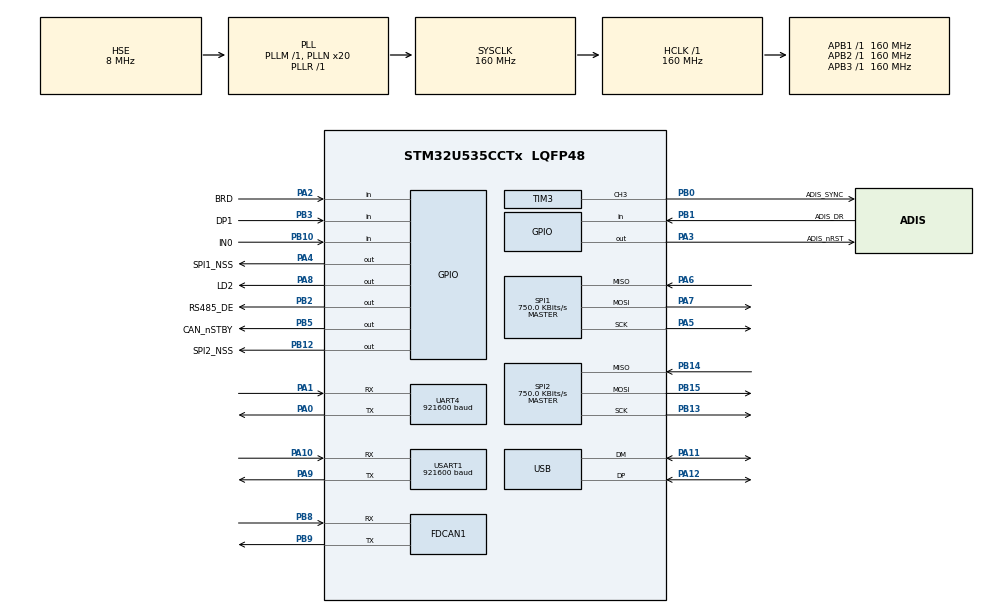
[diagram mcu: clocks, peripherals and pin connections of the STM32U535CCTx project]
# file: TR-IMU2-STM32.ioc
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CORTEX_M33_NS.userName=CORTEX_M33
FDCAN1.CalculateBaudRateNominal=500000
FDCAN1.CalculateTimeBitNominal=2000
FDCAN1.CalculateTimeQuantumNominal=125.0
FDCAN1.ClockDivider=FDCAN_CLOCK_DIV1
FDCAN1.DataPrescaler=2
FDCAN1.DataSyncJumpWidth=4
FDCAN1.DataTimeSeg1=15
FDCAN1.DataTimeSeg2=4
FDCAN1.FrameFormat=FDCAN_FRAME_FD_BRS
FDCAN1.NominalPrescaler=10
FDCAN1.NominalSyncJumpWidth=2
FDCAN1.NominalTimeSeg1=13
FDCAN1.NominalTimeSeg2=2
FDCAN1.ProtocolException=DISABLE
FDCAN1.StdFiltersNbr=1
GPDMA1.IPHANDLE_GPDMACH1-SIMPLEREQUEST_GPDMACH1=__NULL
GPDMA1.IPHANDLE_GPDMACH3-SIMPLEREQUEST_GPDMACH3=__NULL
GPDMA1.LINKEDLISTMODE_GPDMACH0=DMA_LINKEDLIST_CIRCULAR
GPDMA1.LINKEDLISTMODE_GPDMACH2=DMA_LINKEDLIST_CIRCULAR
GPDMA1.PRIORITY_LL_GPDMACH0=DMA_LOW_PRIORITY_HIGH_WEIGHT
GPDMA1.PRIORITY_LL_GPDMACH2=DMA_LOW_PRIORITY_HIGH_WEIGHT
GPDMA1.REQUEST_GPDMACH1=GPDMA1_REQUEST_USART1_TX
GPDMA1.REQUEST_GPDMACH3=GPDMA1_REQUEST_UART4_TX
GPDMA1.SRCINC_GPDMACH1=DMA_SINC_INCREMENTED
GPDMA1.SRCINC_GPDMACH3=DMA_SINC_INCREMENTED
GPDMA1.TRANSFERALLOCATEDPORTDEST_GPDMACH1=DMA_DEST_ALLOCATED_PORT1
GPDMA1.TRANSFERALLOCATEDPORTDEST_GPDMACH3=DMA_DEST_ALLOCATED_PORT1
GPDMA1.TRANSFERALLOCATEDPORTSRC_GPDMACH1=DMA_SRC_ALLOCATED_PORT1
GPDMA1.TRANSFERALLOCATEDPORTSRC_GPDMACH3=DMA_SRC_ALLOCATED_PORT1
IWDG.Prescaler=IWDG_PRESCALER_16
Linkedlist.MDMA_Channel0.GP_SW.0.BlkHWRequest=DMA_BREQ_SINGLE_BURST
Linkedlist.MDMA_Channel0.GP_SW.0.DataHandling=NONE
Linkedlist.MDMA_Channel0.GP_SW.0.DataSize=0
Linkedlist.MDMA_Channel0.GP_SW.0.DestBurstLength=1
Linkedlist.MDMA_Channel0.GP_SW.0.DestDataWidth=DMA_DEST_DATAWIDTH_BYTE
Linkedlist.MDMA_Channel0.GP_SW.0.DestInc=DMA_DINC_INCREMENTED
Linkedlist.MDMA_Channel0.GP_SW.0.Direction=DMA_PERIPH_TO_MEMORY
Linkedlist.MDMA_Channel0.GP_SW.0.DstAddress=0
Linkedlist.MDMA_Channel0.GP_SW.0.Instance=MDMA_Channel0
Linkedlist.MDMA_Channel0.GP_SW.0.LL_CIRCULARNODE=Node_GPDMA1_Channel0
Linkedlist.MDMA_Channel0.GP_SW.0.LL_MASTERDMA=GPDMA
Linkedlist.MDMA_Channel0.GP_SW.0.LL_NAME=UART1Node
Linkedlist.MDMA_Channel0.GP_SW.0.LL_TYPE=CIRCULAR
Linkedlist.MDMA_Channel0.GP_SW.0.NODE_NAME=UART1_RX_node
Linkedlist.MDMA_Channel0.GP_SW.0.Requestforcodegen=GPDMA1_REQUEST_USART1_RX
Linkedlist.MDMA_Channel0.GP_SW.0.SrcAddress=0
Linkedlist.MDMA_Channel0.GP_SW.0.SrcBurstLength=1
Linkedlist.MDMA_Channel0.GP_SW.0.SrcDataWidth=DMA_SRC_DATAWIDTH_BYTE
Linkedlist.MDMA_Channel0.GP_SW.0.SrcInc=DMA_SINC_FIXED
Linkedlist.MDMA_Channel0.GP_SW.0.TransferAllocatedPortDest=DMA_DEST_ALLOCATED_PORT0
Linkedlist.MDMA_Channel0.GP_SW.0.TransferAllocatedPortSrc=DMA_SRC_ALLOCATED_PORT0
Linkedlist.MDMA_Channel0.GP_SW.0.TransferEventMode=DMA_TCEM_BLOCK_TRANSFER
Linkedlist.MDMA_Channel0.GP_SW.0.TriggerPolarity=DMA_TRIG_POLARITY_MASKED
Linkedlist.MDMA_Channel0.Request0=GP_SW
Linkedlist.MDMA_Channel0.RequestsNb=1
Linkedlist.MDMA_Channel1.GP_SW.0.BlkHWRequest=DMA_BREQ_SINGLE_BURST
Linkedlist.MDMA_Channel1.GP_SW.0.DataHandling=NONE
Linkedlist.MDMA_Channel1.GP_SW.0.DataSize=0
Linkedlist.MDMA_Channel1.GP_SW.0.DestBurstLength=1
Linkedlist.MDMA_Channel1.GP_SW.0.DestDataWidth=DMA_DEST_DATAWIDTH_BYTE
Linkedlist.MDMA_Channel1.GP_SW.0.DestInc=DMA_DINC_INCREMENTED
Linkedlist.MDMA_Channel1.GP_SW.0.Direction=DMA_PERIPH_TO_MEMORY
Linkedlist.MDMA_Channel1.GP_SW.0.DstAddress=0
Linkedlist.MDMA_Channel1.GP_SW.0.Instance=MDMA_Channel1
Linkedlist.MDMA_Channel1.GP_SW.0.LL_CIRCULARNODE=Node_GPDMA1_Channel2
Linkedlist.MDMA_Channel1.GP_SW.0.LL_MASTERDMA=GPDMA
Linkedlist.MDMA_Channel1.GP_SW.0.LL_NAME=UART4Node
Linkedlist.MDMA_Channel1.GP_SW.0.LL_TYPE=CIRCULAR
Linkedlist.MDMA_Channel1.GP_SW.0.NODE_NAME=UART4_RX_node
Linkedlist.MDMA_Channel1.GP_SW.0.Requestforcodegen=GPDMA1_REQUEST_UART4_RX
Linkedlist.MDMA_Channel1.GP_SW.0.SrcAddress=0
Linkedlist.MDMA_Channel1.GP_SW.0.SrcBurstLength=1
Linkedlist.MDMA_Channel1.GP_SW.0.SrcDataWidth=DMA_SRC_DATAWIDTH_BYTE
Linkedlist.MDMA_Channel1.GP_SW.0.SrcInc=DMA_SINC_FIXED
Linkedlist.MDMA_Channel1.GP_SW.0.TransferAllocatedPortDest=DMA_DEST_ALLOCATED_PORT0
Linkedlist.MDMA_Channel1.GP_SW.0.TransferAllocatedPortSrc=DMA_SRC_ALLOCATED_PORT0
Linkedlist.MDMA_Channel1.GP_SW.0.TransferEventMode=DMA_TCEM_BLOCK_TRANSFER
Linkedlist.MDMA_Channel1.GP_SW.0.TriggerPolarity=DMA_TRIG_POLARITY_MASKED
Linkedlist.MDMA_Channel1.Request0=GP_SW
Linkedlist.MDMA_Channel1.RequestsNb=1
Linkedlist.RequestSet0=MDMA_Channel0
Linkedlist.RequestSet1=MDMA_Channel1
Linkedlist.RequestSetsNb=2
Mcu.Family=STM32U5
Mcu.Name=STM32U535CCTx
Mcu.Package=LQFP48
NVIC.FDCAN1_IT0_IRQn=true\:2\:0\:true\:false\:true\:true\:true\:true
NVIC.GPDMA1_Channel0_IRQn=true\:2\:0\:true\:false\:true\:true\:true\:true
NVIC.GPDMA1_Channel1_IRQn=true\:2\:0\:true\:false\:true\:false\:true\:true
NVIC.GPDMA1_Channel2_IRQn=true\:2\:0\:true\:false\:true\:true\:true\:true
NVIC.GPDMA1_Channel3_IRQn=true\:2\:0\:true\:false\:true\:false\:true\:true
NVIC.PriorityGroup=NVIC_PRIORITYGROUP_4
NVIC.SPI1_IRQn=true\:1\:0\:true\:false\:true\:true\:true\:true
NVIC.SPI2_IRQn=true\:1\:0\:true\:false\:true\:true\:true\:true
NVIC.TIM6_IRQn=true\:1\:0\:true\:false\:true\:true\:true\:true
NVIC.UART4_IRQn=true\:2\:0\:true\:false\:true\:true\:true\:true
NVIC.USART1_IRQn=true\:2\:0\:true\:false\:true\:true\:true\:true
NVIC.USB_IRQn=true\:0\:0\:true\:false\:true\:true\:true\:true
PA0.GPIO_PuPd=GPIO_PULLUP
PA0.GPIO_Speed=GPIO_SPEED_FREQ_HIGH
PA0.Mode=Asynchronous
PA0.Signal=UART4_TX
PA1.GPIO_PuPd=GPIO_PULLUP
PA1.GPIO_Speed=GPIO_SPEED_FREQ_HIGH
PA1.Mode=Asynchronous
PA1.Signal=UART4_RX
PA10.Mode=Asynchronous
PA10.Signal=USART1_RX
PA11.Mode=Device
PA11.Signal=USB_DM
PA12.Mode=Device
PA12.Signal=USB_DP
PA13\ (JTMS/SWDIO).Mode=Serial_Wire
PA13\ (JTMS/SWDIO).Signal=DEBUG_JTMS-SWDIO
PA14\ (JTCK/SWCLK).Mode=Serial_Wire
PA14\ (JTCK/SWCLK).Signal=DEBUG_JTCK-SWCLK
PA2.GPIO_Label=BRD
PA2.Signal=GPIO_Input
PA3.GPIO_Label=ADIS_nRST
PA3.GPIO_ModeDefaultOutputPP=GPIO_MODE_OUTPUT_OD
PA3.GPIO_PuPd=GPIO_NOPULL
PA3.PinState=GPIO_PIN_SET
PA3.Signal=GPIO_Output
PA4.GPIO_Label=SPI1_NSS
PA4.GPIO_Speed=GPIO_SPEED_FREQ_VERY_HIGH
PA4.PinState=GPIO_PIN_SET
PA4.Signal=GPIO_Output
PA5.GPIO_Speed=GPIO_SPEED_FREQ_VERY_HIGH
PA5.Mode=Full_Duplex_Master
PA5.Signal=SPI1_SCK
PA6.GPIO_Speed=GPIO_SPEED_FREQ_VERY_HIGH
PA6.Mode=Full_Duplex_Master
PA6.Signal=SPI1_MISO
PA7.GPIO_Speed=GPIO_SPEED_FREQ_VERY_HIGH
PA7.Mode=Full_Duplex_Master
PA7.Signal=SPI1_MOSI
PA8.GPIO_Label=LD2
PA8.GPIO_ModeDefaultOutputPP=GPIO_MODE_OUTPUT_OD
PA8.GPIO_PuPd=GPIO_NOPULL
PA8.PinState=GPIO_PIN_SET
PA8.Signal=GPIO_Output
PA9.Mode=Asynchronous
PA9.Signal=USART1_TX
PB0.GPIO_Label=ADIS_SYNC
PB0.GPIO_Speed=GPIO_SPEED_FREQ_HIGH
PB0.Signal=S_TIM3_CH3
PB1.GPIO_Label=ADIS_DR
PB1.Signal=GPIO_Input
PB10.GPIO_Label=IN0
PB10.Signal=GPIO_Input
PB12.GPIO_Label=SPI2_NSS
PB12.GPIO_Speed=GPIO_SPEED_FREQ_VERY_HIGH
PB12.PinState=GPIO_PIN_SET
PB12.Signal=GPIO_Output
PB13.GPIO_Speed=GPIO_SPEED_FREQ_VERY_HIGH
PB13.Mode=Full_Duplex_Master
PB13.Signal=SPI2_SCK
PB14.GPIO_Speed=GPIO_SPEED_FREQ_VERY_HIGH
PB14.Mode=Full_Duplex_Master
PB14.Signal=SPI2_MISO
PB15.GPIO_Speed=GPIO_SPEED_FREQ_VERY_HIGH
PB15.Mode=Full_Duplex_Master
PB15.Signal=SPI2_MOSI
PB2.GPIO_Label=RS485_DE
PB2.GPIO_ModeDefaultOutputPP=GPIO_MODE_OUTPUT_PP
PB2.GPIO_PuPd=GPIO_NOPULL
PB2.GPIO_Speed=GPIO_SPEED_FREQ_HIGH
PB2.PinState=GPIO_PIN_RESET
PB2.Signal=GPIO_Output
PB3\ (JTDO/TRACESWO).GPIO_Label=DP1
PB3\ (JTDO/TRACESWO).GPIO_PuPd=GPIO_PULLUP
PB3\ (JTDO/TRACESWO).Signal=GPIO_Input
PB5.GPIO_Label=CAN_nSTBY
PB5.GPIO_ModeDefaultOutputPP=GPIO_MODE_OUTPUT_OD
PB5.GPIO_PuPd=GPIO_NOPULL
PB5.PinState=GPIO_PIN_SET
PB5.Signal=GPIO_Output
PB8.Mode=FDCAN_Activate
PB8.Signal=FDCAN1_RX
PB9.Mode=FDCAN_Activate
PB9.Signal=FDCAN1_TX
PH0-OSC_IN\ (PH0).Mode=HSE-External-Oscillator
PH0-OSC_IN\ (PH0).Signal=RCC_OSC_IN
PH1-OSC_OUT\ (PH1).Mode=HSE-External-Oscillator
PH1-OSC_OUT\ (PH1).Signal=RCC_OSC_OUT
ProjectManager.HeapSize=0x800
ProjectManager.StackSize=0x800
ProjectManager.TargetToolchain=STM32CubeIDE
RCC.ADCFreq_Value=16000000
RCC.AHBFreq_Value=160000000
RCC.APB1Freq_Value=160000000
RCC.APB1TimFreq_Value=160000000
RCC.APB2Freq_Value=160000000
RCC.APB2TimFreq_Value=160000000
RCC.APB3Freq_Value=160000000
RCC.CortexFreq_Value=160000000
RCC.DACCLockSelectionVirtual=RCC_DAC1CLKSOURCE_LSI
RCC.DACCLockSelectionVirtualString=RCC_DAC1CLKSOURCE_LSI
RCC.EPOD_VALUE=8000000
RCC.HCLKFreq_Value=160000000
RCC.HSE_VALUE=8000000
RCC.HSI48_VALUE=48000000
RCC.HSI_VALUE=16000000
RCC.LSE_VALUE=32768
RCC.LSIDIV_VALUE=32000
RCC.MSIClockRange=RCC_MSIRANGE_0
RCC.MSIKClockRange=RCC_MSIKRANGE_1
RCC.MSI_VALUE=48000000
RCC.PLL1R=1
RCC.PLL2FRACN=0
RCC.PLL3FRACN=0
RCC.PLLFRACN=0
RCC.PLLN=20
RCC.PLLSourceVirtual=RCC_PLLSOURCE_HSE
RCC.SPI1CLockSelection=RCC_SPI1CLKSOURCE_MSIK
RCC.SPI2CLockSelection=RCC_SPI2CLKSOURCE_MSIK
RCC.SYSCLKFreq_VALUE=160000000
RCC.SYSCLKSource=RCC_SYSCLKSOURCE_PLLCLK
RCC.USBFreq_Value=48000000
RCC.VCOOutputFreq_Value=160000000
SH.S_TIM3_CH3.0=TIM3_CH3,PWM Generation3 CH3
SPI1.BaudRatePrescaler=SPI_BAUDRATEPRESCALER_32
SPI1.CLKPhase=SPI_PHASE_2EDGE
SPI1.CLKPolarity=SPI_POLARITY_HIGH
SPI1.CalculateBaudRate=750.0 KBits/s
SPI1.DataSize=SPI_DATASIZE_16BIT
SPI1.Direction=SPI_DIRECTION_2LINES
SPI1.Mode=SPI_MODE_MASTER
SPI1.VirtualType=VM_MASTER
SPI2.BaudRatePrescaler=SPI_BAUDRATEPRESCALER_32
SPI2.CLKPhase=SPI_PHASE_2EDGE
SPI2.CLKPolarity=SPI_POLARITY_HIGH
SPI2.CalculateBaudRate=750.0 KBits/s
SPI2.DataSize=SPI_DATASIZE_16BIT
SPI2.Direction=SPI_DIRECTION_2LINES
SPI2.Mode=SPI_MODE_MASTER
SPI2.VirtualType=VM_MASTER
TIM3.AutoReloadPreload=TIM_AUTORELOAD_PRELOAD_ENABLE
TIM3.Channel-PWM\ Generation3\ CH3=TIM_CHANNEL_3
TIM3.PeriodNoDither=5786
TIM3.Prescaler=2
TIM3.PulseNoDither_3=2500
TIM6.PeriodNoDither=159
TIM6.Prescaler=15
TIM6.TIM_MasterOutputTrigger=TIM_TRGO_UPDATE
UART4.BaudRate=921600
USART1.BaudRate=921600
USART1.VirtualMode-Asynchronous=VM_ASYNC
VP_DCACHE1_VS_DCACHE.Mode=DCACHE_Activate
VP_GPDMA1_VS_GPDMACH0.Mode=LINKEDLIST_GPDMACH0
VP_GPDMA1_VS_GPDMACH1.Mode=SIMPLEREQUEST_GPDMACH1
VP_GPDMA1_VS_GPDMACH2.Mode=LINKEDLIST_GPDMACH2
VP_GPDMA1_VS_GPDMACH3.Mode=SIMPLEREQUEST_GPDMACH3
VP_ICACHE_VS_ICACHE.Mode=DefaultMode
VP_IWDG_VS_IWDG.Mode=IWDG_Activate
VP_LPBAMQUEUE_VS_QUEUE.Mode=QUEUEMODE
VP_LPBAM_VS_SIG1.Mode=SmartRun
VP_LPBAM_VS_SIG4.Mode=LPDMA1
VP_MEMORYMAP_VS_MEMORYMAP.Mode=CurAppReg
VP_PWR_VS_SECSignals.Mode=Security/Privilege
VP_TIM3_VS_ClockSourceINT.Mode=Internal
VP_TIM6_VS_ClockSourceINT.Mode=Enable_Timer
VP_TIM6_VS_OPM.Mode=OPM_bit
board=custom

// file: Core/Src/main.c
/* USER CODE BEGIN Header */
/**
  ******************************************************************************
  * @file           : main.c
  * @brief          : Main program body
  ******************************************************************************
  * @attention
  *
  * Copyright (c) 2025 STMicroelectronics.
  * All rights reserved.
  *
  * This software is licensed under terms that can be found in the LICENSE file
  * in the root directory of this software component.
  * If no LICENSE file comes with this software, it is provided AS-IS.
  *
  ******************************************************************************
  */
/* USER CODE END Header */
#include "main.h"

/* USER CODE BEGIN Includes */
#include "libraries.h"
/* USER CODE END Includes */

DCACHE_HandleTypeDef hdcache1;

FDCAN_HandleTypeDef hfdcan1;

DMA_HandleTypeDef handle_GPDMA1_Channel2;
DMA_HandleTypeDef handle_GPDMA1_Channel0;

UART_HandleTypeDef huart4;
UART_HandleTypeDef huart1;
DMA_HandleTypeDef handle_GPDMA1_Channel3;
DMA_HandleTypeDef handle_GPDMA1_Channel1;

PCD_HandleTypeDef hpcd_USB_DRD_FS;

void SystemClock_Config(void);
static void MX_GPIO_Init(void);
static void MX_GPDMA1_Init(void);
static void MX_ICACHE_Init(void);
static void MX_DCACHE1_Init(void);
static void MX_SPI1_Init(void);
static void MX_SPI2_Init(void);
static void MX_TIM3_Init(void);
static void MX_TIM6_Init(void);
static void MX_FDCAN1_Init(void);
static void MX_USART1_UART_Init(void);
static void MX_UART4_Init(void);
static void MX_USB_DRD_FS_PCD_Init(void);

int main(void)
{

  /* MCU Configuration--------------------------------------------------------*/

  /* Reset of all peripherals, Initializes the Flash interface and the Systick. */
  HAL_Init();

  /* USER CODE BEGIN Init */
  LL_PWR_EnableVDDA();
  /* USER CODE END Init */

  /* Configure the system clock */
  SystemClock_Config();

  /* Initialize all configured peripherals */
  MX_GPIO_Init();
  MX_GPDMA1_Init();
  MX_ICACHE_Init();
  MX_DCACHE1_Init();
  MX_SPI1_Init();
  MX_SPI2_Init();
  MX_TIM3_Init();
  MX_TIM6_Init();
  MX_FDCAN1_Init();
  MX_USART1_UART_Init();
  MX_UART4_Init();
  MX_USB_DRD_FS_PCD_Init();
  /* USER CODE BEGIN 2 */
  MX_USB_DEVICE_Init();
  setup();
  /* USER CODE END 2 */

  /* Infinite loop */
  /* USER CODE BEGIN WHILE */
  while (1)
  {
    loop();
    /* USER CODE END WHILE */

  }
}

void SystemClock_Config(void)
{
  RCC_OscInitTypeDef RCC_OscInitStruct = {0};
  RCC_ClkInitTypeDef RCC_ClkInitStruct = {0};

  /** Configure the main internal regulator output voltage
  */
  if (HAL_PWREx_ControlVoltageScaling(PWR_REGULATOR_VOLTAGE_SCALE1) != HAL_OK)
  {
    Error_Handler();
  }

  /** Initializes the CPU, AHB and APB buses clocks
  */
  RCC_OscInitStruct.OscillatorType = RCC_OSCILLATORTYPE_HSI48|RCC_OSCILLATORTYPE_LSI
                              |RCC_OSCILLATORTYPE_HSE|RCC_OSCILLATORTYPE_MSIK;
  RCC_OscInitStruct.HSEState = RCC_HSE_ON;
  RCC_OscInitStruct.HSI48State = RCC_HSI48_ON;
  RCC_OscInitStruct.LSIState = RCC_LSI_ON;
  RCC_OscInitStruct.MSICalibrationValue = RCC_MSICALIBRATION_DEFAULT;
  RCC_OscInitStruct.LSIDiv = RCC_LSI_DIV1;
  RCC_OscInitStruct.MSIKClockRange = RCC_MSIKRANGE_1;
  RCC_OscInitStruct.MSIKState = RCC_MSIK_ON;
  RCC_OscInitStruct.PLL.PLLState = RCC_PLL_ON;
  RCC_OscInitStruct.PLL.PLLSource = RCC_PLLSOURCE_HSE;
  RCC_OscInitStruct.PLL.PLLMBOOST = RCC_PLLMBOOST_DIV1;
  RCC_OscInitStruct.PLL.PLLM = 1;
  RCC_OscInitStruct.PLL.PLLN = 20;
  RCC_OscInitStruct.PLL.PLLP = 2;
  RCC_OscInitStruct.PLL.PLLQ = 2;
  RCC_OscInitStruct.PLL.PLLR = 1;
  RCC_OscInitStruct.PLL.PLLRGE = RCC_PLLVCIRANGE_1;
  RCC_OscInitStruct.PLL.PLLFRACN = 0;
  if (HAL_RCC_OscConfig(&RCC_OscInitStruct) != HAL_OK)
  {
    Error_Handler();
  }

  /** Initializes the CPU, AHB and APB buses clocks
  */
  RCC_ClkInitStruct.ClockType = RCC_CLOCKTYPE_HCLK|RCC_CLOCKTYPE_SYSCLK
                              |RCC_CLOCKTYPE_PCLK1|RCC_CLOCKTYPE_PCLK2
                              |RCC_CLOCKTYPE_PCLK3;
  RCC_ClkInitStruct.SYSCLKSource = RCC_SYSCLKSOURCE_PLLCLK;
  RCC_ClkInitStruct.AHBCLKDivider = RCC_SYSCLK_DIV1;
  RCC_ClkInitStruct.APB1CLKDivider = RCC_HCLK_DIV1;
  RCC_ClkInitStruct.APB2CLKDivider = RCC_HCLK_DIV1;
  RCC_ClkInitStruct.APB3CLKDivider = RCC_HCLK_DIV1;

  if (HAL_RCC_ClockConfig(&RCC_ClkInitStruct, FLASH_LATENCY_4) != HAL_OK)
  {
    Error_Handler();
  }
}

static void MX_DCACHE1_Init(void)
{

  hdcache1.Instance = DCACHE1;
  hdcache1.Init.ReadBurstType = DCACHE_READ_BURST_WRAP;
  if (HAL_DCACHE_Init(&hdcache1) != HAL_OK)
  {
    Error_Handler();
  }

}

static void MX_FDCAN1_Init(void)
{

  hfdcan1.Instance = FDCAN1;
  hfdcan1.Init.ClockDivider = FDCAN_CLOCK_DIV1;
  hfdcan1.Init.FrameFormat = FDCAN_FRAME_FD_BRS;
  hfdcan1.Init.Mode = FDCAN_MODE_NORMAL;
  hfdcan1.Init.AutoRetransmission = DISABLE;
  hfdcan1.Init.TransmitPause = DISABLE;
  hfdcan1.Init.ProtocolException = DISABLE;
  hfdcan1.Init.NominalPrescaler = 10;
  hfdcan1.Init.NominalSyncJumpWidth = 2;
  hfdcan1.Init.NominalTimeSeg1 = 13;
  hfdcan1.Init.NominalTimeSeg2 = 2;
  hfdcan1.Init.DataPrescaler = 2;
  hfdcan1.Init.DataSyncJumpWidth = 4;
  hfdcan1.Init.DataTimeSeg1 = 15;
  hfdcan1.Init.DataTimeSeg2 = 4;
  hfdcan1.Init.StdFiltersNbr = 1;
  hfdcan1.Init.ExtFiltersNbr = 0;
  hfdcan1.Init.TxFifoQueueMode = FDCAN_TX_FIFO_OPERATION;
  if (HAL_FDCAN_Init(&hfdcan1) != HAL_OK)
  {
    Error_Handler();
  }

}

static void MX_GPDMA1_Init(void)
{

  /* Peripheral clock enable */
  __HAL_RCC_GPDMA1_CLK_ENABLE();

  /* GPDMA1 interrupt Init */
    HAL_NVIC_SetPriority(GPDMA1_Channel0_IRQn, 2, 0);
    HAL_NVIC_EnableIRQ(GPDMA1_Channel0_IRQn);
    HAL_NVIC_SetPriority(GPDMA1_Channel1_IRQn, 2, 0);
    HAL_NVIC_EnableIRQ(GPDMA1_Channel1_IRQn);
    HAL_NVIC_SetPriority(GPDMA1_Channel2_IRQn, 2, 0);
    HAL_NVIC_EnableIRQ(GPDMA1_Channel2_IRQn);
    HAL_NVIC_SetPriority(GPDMA1_Channel3_IRQn, 2, 0);
    HAL_NVIC_EnableIRQ(GPDMA1_Channel3_IRQn);

  handle_GPDMA1_Channel2.Instance = GPDMA1_Channel2;
  handle_GPDMA1_Channel2.InitLinkedList.Priority = DMA_LOW_PRIORITY_HIGH_WEIGHT;
  handle_GPDMA1_Channel2.InitLinkedList.LinkStepMode = DMA_LSM_FULL_EXECUTION;
  handle_GPDMA1_Channel2.InitLinkedList.LinkAllocatedPort = DMA_LINK_ALLOCATED_PORT0;
  handle_GPDMA1_Channel2.InitLinkedList.TransferEventMode = DMA_TCEM_LAST_LL_ITEM_TRANSFER;
  handle_GPDMA1_Channel2.InitLinkedList.LinkedListMode = DMA_LINKEDLIST_CIRCULAR;
  if (HAL_DMAEx_List_Init(&handle_GPDMA1_Channel2) != HAL_OK)
  {
    Error_Handler();
  }
  if (HAL_DMA_ConfigChannelAttributes(&handle_GPDMA1_Channel2, DMA_CHANNEL_NPRIV) != HAL_OK)
  {
    Error_Handler();
  }
  handle_GPDMA1_Channel0.Instance = GPDMA1_Channel0;
  handle_GPDMA1_Channel0.InitLinkedList.Priority = DMA_LOW_PRIORITY_HIGH_WEIGHT;
  handle_GPDMA1_Channel0.InitLinkedList.LinkStepMode = DMA_LSM_FULL_EXECUTION;
  handle_GPDMA1_Channel0.InitLinkedList.LinkAllocatedPort = DMA_LINK_ALLOCATED_PORT0;
  handle_GPDMA1_Channel0.InitLinkedList.TransferEventMode = DMA_TCEM_LAST_LL_ITEM_TRANSFER;
  handle_GPDMA1_Channel0.InitLinkedList.LinkedListMode = DMA_LINKEDLIST_CIRCULAR;
  if (HAL_DMAEx_List_Init(&handle_GPDMA1_Channel0) != HAL_OK)
  {
    Error_Handler();
  }
  if (HAL_DMA_ConfigChannelAttributes(&handle_GPDMA1_Channel0, DMA_CHANNEL_NPRIV) != HAL_OK)
  {
    Error_Handler();
  }

}

static void MX_ICACHE_Init(void)
{

  /** Enable instruction cache (default 2-ways set associative cache)
  */
  if (HAL_ICACHE_Enable() != HAL_OK)
  {
    Error_Handler();
  }

}

void MX_IWDG_Init(void)
{

  LL_IWDG_Enable(IWDG);
  LL_IWDG_EnableWriteAccess(IWDG);
  LL_IWDG_SetPrescaler(IWDG, LL_IWDG_PRESCALER_16);
  LL_IWDG_SetReloadCounter(IWDG, 4095);
  while (LL_IWDG_IsReady(IWDG) != 1)
  {
  }

  LL_IWDG_ReloadCounter(IWDG);

}

static void MX_SPI1_Init(void)
{

  LL_SPI_InitTypeDef SPI_InitStruct = {0};

  LL_GPIO_InitTypeDef GPIO_InitStruct = {0};
  RCC_PeriphCLKInitTypeDef PeriphClkInit = {0};

  /** Initializes the peripherals clock
  */
  PeriphClkInit.PeriphClockSelection = RCC_PERIPHCLK_SPI1;
  PeriphClkInit.Spi1ClockSelection = RCC_SPI1CLKSOURCE_MSIK;
  if (HAL_RCCEx_PeriphCLKConfig(&PeriphClkInit) != HAL_OK)
  {
    Error_Handler();
  }

  /* Peripheral clock enable */
  LL_APB2_GRP1_EnableClock(LL_APB2_GRP1_PERIPH_SPI1);

  LL_AHB2_GRP1_EnableClock(LL_AHB2_GRP1_PERIPH_GPIOA);
  /**SPI1 GPIO Configuration
  PA5   ------> SPI1_SCK
  PA6   ------> SPI1_MISO
  PA7   ------> SPI1_MOSI
  */
  GPIO_InitStruct.Pin = LL_GPIO_PIN_5|LL_GPIO_PIN_6|LL_GPIO_PIN_7;
  GPIO_InitStruct.Mode = LL_GPIO_MODE_ALTERNATE;
  GPIO_InitStruct.Speed = LL_GPIO_SPEED_FREQ_VERY_HIGH;
  GPIO_InitStruct.OutputType = LL_GPIO_OUTPUT_PUSHPULL;
  GPIO_InitStruct.Pull = LL_GPIO_PULL_NO;
  GPIO_InitStruct.Alternate = LL_GPIO_AF_5;
  LL_GPIO_Init(GPIOA, &GPIO_InitStruct);

  /* SPI1 interrupt Init */
  NVIC_SetPriority(SPI1_IRQn, NVIC_EncodePriority(NVIC_GetPriorityGrouping(),1, 0));
  NVIC_EnableIRQ(SPI1_IRQn);

  /* SPI1 parameter configuration*/
  SPI_InitStruct.TransferDirection = LL_SPI_FULL_DUPLEX;
  SPI_InitStruct.Mode = LL_SPI_MODE_MASTER;
  SPI_InitStruct.DataWidth = LL_SPI_DATAWIDTH_16BIT;
  SPI_InitStruct.ClockPolarity = LL_SPI_POLARITY_HIGH;
  SPI_InitStruct.ClockPhase = LL_SPI_PHASE_2EDGE;
  SPI_InitStruct.NSS = LL_SPI_NSS_SOFT;
  SPI_InitStruct.BaudRate = LL_SPI_BAUDRATEPRESCALER_DIV32;
  SPI_InitStruct.BitOrder = LL_SPI_MSB_FIRST;
  SPI_InitStruct.CRCCalculation = LL_SPI_CRCCALCULATION_DISABLE;
  SPI_InitStruct.CRCPoly = 0x7;
  LL_SPI_Init(SPI1, &SPI_InitStruct);
  LL_SPI_SetStandard(SPI1, LL_SPI_PROTOCOL_MOTOROLA);
  LL_SPI_DisableNSSPulseMgt(SPI1);

}

static void MX_SPI2_Init(void)
{

  LL_SPI_InitTypeDef SPI_InitStruct = {0};

  LL_GPIO_InitTypeDef GPIO_InitStruct = {0};
  RCC_PeriphCLKInitTypeDef PeriphClkInit = {0};

  /** Initializes the peripherals clock
  */
  PeriphClkInit.PeriphClockSelection = RCC_PERIPHCLK_SPI2;
  PeriphClkInit.Spi2ClockSelection = RCC_SPI2CLKSOURCE_MSIK;
  if (HAL_RCCEx_PeriphCLKConfig(&PeriphClkInit) != HAL_OK)
  {
    Error_Handler();
  }

  /* Peripheral clock enable */
  LL_APB1_GRP1_EnableClock(LL_APB1_GRP1_PERIPH_SPI2);

  LL_AHB2_GRP1_EnableClock(LL_AHB2_GRP1_PERIPH_GPIOB);
  /**SPI2 GPIO Configuration
  PB13   ------> SPI2_SCK
  PB14   ------> SPI2_MISO
  PB15   ------> SPI2_MOSI
  */
  GPIO_InitStruct.Pin = LL_GPIO_PIN_13|LL_GPIO_PIN_14|LL_GPIO_PIN_15;
  GPIO_InitStruct.Mode = LL_GPIO_MODE_ALTERNATE;
  GPIO_InitStruct.Speed = LL_GPIO_SPEED_FREQ_VERY_HIGH;
  GPIO_InitStruct.OutputType = LL_GPIO_OUTPUT_PUSHPULL;
  GPIO_InitStruct.Pull = LL_GPIO_PULL_NO;
  GPIO_InitStruct.Alternate = LL_GPIO_AF_5;
  LL_GPIO_Init(GPIOB, &GPIO_InitStruct);

  /* SPI2 interrupt Init */
  NVIC_SetPriority(SPI2_IRQn, NVIC_EncodePriority(NVIC_GetPriorityGrouping(),1, 0));
  NVIC_EnableIRQ(SPI2_IRQn);

  /* SPI2 parameter configuration*/
  SPI_InitStruct.TransferDirection = LL_SPI_FULL_DUPLEX;
  SPI_InitStruct.Mode = LL_SPI_MODE_MASTER;
  SPI_InitStruct.DataWidth = LL_SPI_DATAWIDTH_16BIT;
  SPI_InitStruct.ClockPolarity = LL_SPI_POLARITY_HIGH;
  SPI_InitStruct.ClockPhase = LL_SPI_PHASE_2EDGE;
  SPI_InitStruct.NSS = LL_SPI_NSS_SOFT;
  SPI_InitStruct.BaudRate = LL_SPI_BAUDRATEPRESCALER_DIV32;
  SPI_InitStruct.BitOrder = LL_SPI_MSB_FIRST;
  SPI_InitStruct.CRCCalculation = LL_SPI_CRCCALCULATION_DISABLE;
  SPI_InitStruct.CRCPoly = 0x7;
  LL_SPI_Init(SPI2, &SPI_InitStruct);
  LL_SPI_SetStandard(SPI2, LL_SPI_PROTOCOL_MOTOROLA);
  LL_SPI_DisableNSSPulseMgt(SPI2);

}

static void MX_TIM3_Init(void)
{

  LL_TIM_InitTypeDef TIM_InitStruct = {0};
  LL_TIM_OC_InitTypeDef TIM_OC_InitStruct = {0};

  LL_GPIO_InitTypeDef GPIO_InitStruct = {0};

  /* Peripheral clock enable */
  LL_APB1_GRP1_EnableClock(LL_APB1_GRP1_PERIPH_TIM3);

  TIM_InitStruct.Prescaler = 2;
  TIM_InitStruct.CounterMode = LL_TIM_COUNTERMODE_UP;
  TIM_InitStruct.Autoreload = 5786;
  TIM_InitStruct.ClockDivision = LL_TIM_CLOCKDIVISION_DIV1;
  LL_TIM_Init(TIM3, &TIM_InitStruct);
  LL_TIM_EnableARRPreload(TIM3);
  LL_TIM_SetClockSource(TIM3, LL_TIM_CLOCKSOURCE_INTERNAL);
  LL_TIM_OC_EnablePreload(TIM3, LL_TIM_CHANNEL_CH3);
  TIM_OC_InitStruct.OCMode = LL_TIM_OCMODE_PWM1;
  TIM_OC_InitStruct.OCState = LL_TIM_OCSTATE_DISABLE;
  TIM_OC_InitStruct.OCNState = LL_TIM_OCSTATE_DISABLE;
  TIM_OC_InitStruct.CompareValue = 2500;
  TIM_OC_InitStruct.OCPolarity = LL_TIM_OCPOLARITY_HIGH;
  LL_TIM_OC_Init(TIM3, LL_TIM_CHANNEL_CH3, &TIM_OC_InitStruct);
  LL_TIM_OC_DisableFast(TIM3, LL_TIM_CHANNEL_CH3);
  LL_TIM_SetTriggerOutput(TIM3, LL_TIM_TRGO_RESET);
  LL_TIM_DisableMasterSlaveMode(TIM3);
  LL_AHB2_GRP1_EnableClock(LL_AHB2_GRP1_PERIPH_GPIOB);
  /**TIM3 GPIO Configuration
  PB0   ------> TIM3_CH3
  */
  GPIO_InitStruct.Pin = ADIS_SYNC_Pin;
  GPIO_InitStruct.Mode = LL_GPIO_MODE_ALTERNATE;
  GPIO_InitStruct.Speed = LL_GPIO_SPEED_FREQ_HIGH;
  GPIO_InitStruct.OutputType = LL_GPIO_OUTPUT_PUSHPULL;
  GPIO_InitStruct.Pull = LL_GPIO_PULL_NO;
  GPIO_InitStruct.Alternate = LL_GPIO_AF_2;
  LL_GPIO_Init(ADIS_SYNC_GPIO_Port, &GPIO_InitStruct);

}

static void MX_TIM6_Init(void)
{

  LL_TIM_InitTypeDef TIM_InitStruct = {0};

  /* Peripheral clock enable */
  LL_APB1_GRP1_EnableClock(LL_APB1_GRP1_PERIPH_TIM6);

  /* TIM6 interrupt Init */
  NVIC_SetPriority(TIM6_IRQn, NVIC_EncodePriority(NVIC_GetPriorityGrouping(),1, 0));
  NVIC_EnableIRQ(TIM6_IRQn);

  TIM_InitStruct.Prescaler = 15;
  TIM_InitStruct.CounterMode = LL_TIM_COUNTERMODE_UP;
  TIM_InitStruct.Autoreload = 159;
  LL_TIM_Init(TIM6, &TIM_InitStruct);
  LL_TIM_DisableARRPreload(TIM6);
  LL_TIM_SetOnePulseMode(TIM6, LL_TIM_ONEPULSEMODE_SINGLE);
  LL_TIM_SetTriggerOutput(TIM6, LL_TIM_TRGO_UPDATE);
  LL_TIM_DisableMasterSlaveMode(TIM6);

}

static void MX_UART4_Init(void)
{

  huart4.Instance = UART4;
  huart4.Init.BaudRate = 921600;
  huart4.Init.WordLength = UART_WORDLENGTH_8B;
  huart4.Init.StopBits = UART_STOPBITS_1;
  huart4.Init.Parity = UART_PARITY_NONE;
  huart4.Init.Mode = UART_MODE_TX_RX;
  huart4.Init.HwFlowCtl = UART_HWCONTROL_NONE;
  huart4.Init.OverSampling = UART_OVERSAMPLING_16;
  huart4.Init.OneBitSampling = UART_ONE_BIT_SAMPLE_DISABLE;
  huart4.Init.ClockPrescaler = UART_PRESCALER_DIV1;
  huart4.AdvancedInit.AdvFeatureInit = UART_ADVFEATURE_NO_INIT;
  if (HAL_UART_Init(&huart4) != HAL_OK)
  {
    Error_Handler();
  }
  if (HAL_UARTEx_SetTxFifoThreshold(&huart4, UART_TXFIFO_THRESHOLD_1_8) != HAL_OK)
  {
    Error_Handler();
  }
  if (HAL_UARTEx_SetRxFifoThreshold(&huart4, UART_RXFIFO_THRESHOLD_1_8) != HAL_OK)
  {
    Error_Handler();
  }
  if (HAL_UARTEx_DisableFifoMode(&huart4) != HAL_OK)
  {
    Error_Handler();
  }

}

static void MX_USART1_UART_Init(void)
{

  huart1.Instance = USART1;
  huart1.Init.BaudRate = 921600;
  huart1.Init.WordLength = UART_WORDLENGTH_8B;
  huart1.Init.StopBits = UART_STOPBITS_1;
  huart1.Init.Parity = UART_PARITY_NONE;
  huart1.Init.Mode = UART_MODE_TX_RX;
  huart1.Init.HwFlowCtl = UART_HWCONTROL_NONE;
  huart1.Init.OverSampling = UART_OVERSAMPLING_16;
  huart1.Init.OneBitSampling = UART_ONE_BIT_SAMPLE_DISABLE;
  huart1.Init.ClockPrescaler = UART_PRESCALER_DIV1;
  huart1.AdvancedInit.AdvFeatureInit = UART_ADVFEATURE_NO_INIT;
  if (HAL_UART_Init(&huart1) != HAL_OK)
  {
    Error_Handler();
  }
  if (HAL_UARTEx_SetTxFifoThreshold(&huart1, UART_TXFIFO_THRESHOLD_1_8) != HAL_OK)
  {
    Error_Handler();
  }
  if (HAL_UARTEx_SetRxFifoThreshold(&huart1, UART_RXFIFO_THRESHOLD_1_8) != HAL_OK)
  {
    Error_Handler();
  }
  if (HAL_UARTEx_DisableFifoMode(&huart1) != HAL_OK)
  {
    Error_Handler();
  }

}

static void MX_USB_DRD_FS_PCD_Init(void)
{

  hpcd_USB_DRD_FS.Instance = USB_DRD_FS;
  hpcd_USB_DRD_FS.Init.dev_endpoints = 8;
  hpcd_USB_DRD_FS.Init.speed = PCD_SPEED_FULL;
  hpcd_USB_DRD_FS.Init.phy_itface = PCD_PHY_EMBEDDED;
  hpcd_USB_DRD_FS.Init.Sof_enable = DISABLE;
  hpcd_USB_DRD_FS.Init.low_power_enable = DISABLE;
  hpcd_USB_DRD_FS.Init.lpm_enable = DISABLE;
  hpcd_USB_DRD_FS.Init.battery_charging_enable = DISABLE;
  hpcd_USB_DRD_FS.Init.vbus_sensing_enable = DISABLE;
  hpcd_USB_DRD_FS.Init.bulk_doublebuffer_enable = DISABLE;
  hpcd_USB_DRD_FS.Init.iso_singlebuffer_enable = DISABLE;
  if (HAL_PCD_Init(&hpcd_USB_DRD_FS) != HAL_OK)
  {
    Error_Handler();
  }

}

static void MX_GPIO_Init(void)
{
  LL_GPIO_InitTypeDef GPIO_InitStruct = {0};

  /* GPIO Ports Clock Enable */
  LL_AHB2_GRP1_EnableClock(LL_AHB2_GRP1_PERIPH_GPIOH);
  LL_AHB2_GRP1_EnableClock(LL_AHB2_GRP1_PERIPH_GPIOA);
  LL_AHB2_GRP1_EnableClock(LL_AHB2_GRP1_PERIPH_GPIOB);

  /**/
  LL_GPIO_SetOutputPin(GPIOA, ADIS_nRST_Pin|SPI1_NSS_Pin|LD2_Pin);

  /**/
  LL_GPIO_SetOutputPin(GPIOB, SPI2_NSS_Pin|CAN_nSTBY_Pin);

  /**/
  LL_GPIO_ResetOutputPin(RS485_DE_GPIO_Port, RS485_DE_Pin);

  /**/
  GPIO_InitStruct.Pin = BRD_Pin;
  GPIO_InitStruct.Mode = LL_GPIO_MODE_INPUT;
  GPIO_InitStruct.Pull = LL_GPIO_PULL_NO;
  LL_GPIO_Init(BRD_GPIO_Port, &GPIO_InitStruct);

  /**/
  GPIO_InitStruct.Pin = ADIS_nRST_Pin|LD2_Pin;
  GPIO_InitStruct.Mode = LL_GPIO_MODE_OUTPUT;
  GPIO_InitStruct.Speed = LL_GPIO_SPEED_FREQ_LOW;
  GPIO_InitStruct.OutputType = LL_GPIO_OUTPUT_OPENDRAIN;
  GPIO_InitStruct.Pull = LL_GPIO_PULL_NO;
  LL_GPIO_Init(GPIOA, &GPIO_InitStruct);

  /**/
  GPIO_InitStruct.Pin = SPI1_NSS_Pin;
  GPIO_InitStruct.Mode = LL_GPIO_MODE_OUTPUT;
  GPIO_InitStruct.Speed = LL_GPIO_SPEED_FREQ_VERY_HIGH;
  GPIO_InitStruct.OutputType = LL_GPIO_OUTPUT_PUSHPULL;
  GPIO_InitStruct.Pull = LL_GPIO_PULL_NO;
  LL_GPIO_Init(SPI1_NSS_GPIO_Port, &GPIO_InitStruct);

  /**/
  GPIO_InitStruct.Pin = ADIS_DR_Pin|IN0_Pin;
  GPIO_InitStruct.Mode = LL_GPIO_MODE_INPUT;
  GPIO_InitStruct.Pull = LL_GPIO_PULL_NO;
  LL_GPIO_Init(GPIOB, &GPIO_InitStruct);

  /**/
  GPIO_InitStruct.Pin = RS485_DE_Pin;
  GPIO_InitStruct.Mode = LL_GPIO_MODE_OUTPUT;
  GPIO_InitStruct.Speed = LL_GPIO_SPEED_FREQ_HIGH;
  GPIO_InitStruct.OutputType = LL_GPIO_OUTPUT_PUSHPULL;
  GPIO_InitStruct.Pull = LL_GPIO_PULL_NO;
  LL_GPIO_Init(RS485_DE_GPIO_Port, &GPIO_InitStruct);

  /**/
  GPIO_InitStruct.Pin = SPI2_NSS_Pin;
  GPIO_InitStruct.Mode = LL_GPIO_MODE_OUTPUT;
  GPIO_InitStruct.Speed = LL_GPIO_SPEED_FREQ_VERY_HIGH;
  GPIO_InitStruct.OutputType = LL_GPIO_OUTPUT_PUSHPULL;
  GPIO_InitStruct.Pull = LL_GPIO_PULL_NO;
  LL_GPIO_Init(SPI2_NSS_GPIO_Port, &GPIO_InitStruct);

  /**/
  GPIO_InitStruct.Pin = DP1_Pin;
  GPIO_InitStruct.Mode = LL_GPIO_MODE_INPUT;
  GPIO_InitStruct.Pull = LL_GPIO_PULL_UP;
  LL_GPIO_Init(DP1_GPIO_Port, &GPIO_InitStruct);

  /**/
  GPIO_InitStruct.Pin = CAN_nSTBY_Pin;
  GPIO_InitStruct.Mode = LL_GPIO_MODE_OUTPUT;
  GPIO_InitStruct.Speed = LL_GPIO_SPEED_FREQ_LOW;
  GPIO_InitStruct.OutputType = LL_GPIO_OUTPUT_OPENDRAIN;
  GPIO_InitStruct.Pull = LL_GPIO_PULL_NO;
  LL_GPIO_Init(CAN_nSTBY_GPIO_Port, &GPIO_InitStruct);

}

void Error_Handler(void)
{
  __disable_irq();
  while (1)
  {
  }
}
